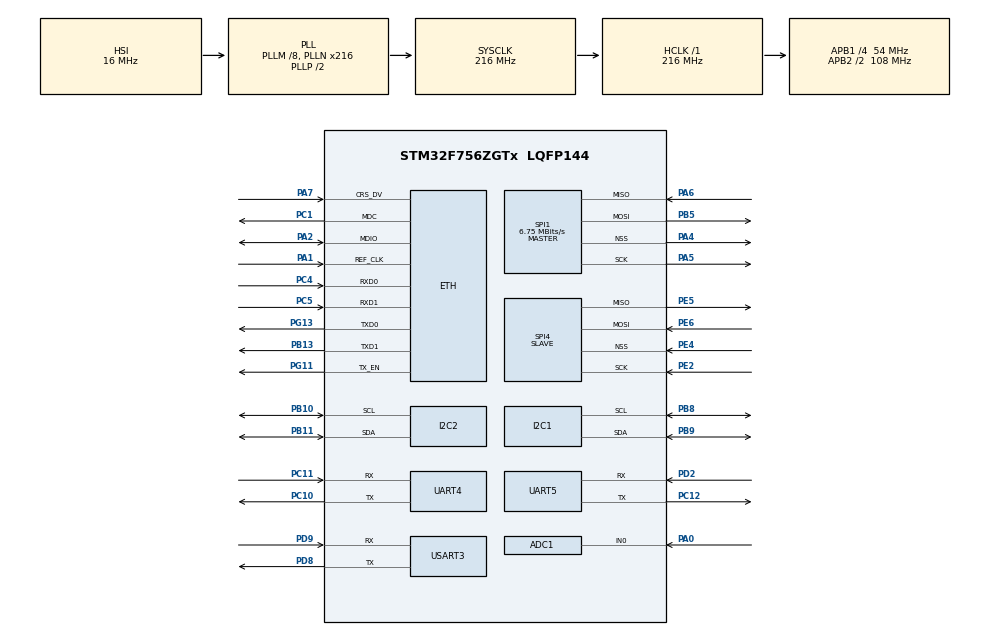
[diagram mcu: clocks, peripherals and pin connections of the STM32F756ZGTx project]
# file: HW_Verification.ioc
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ADC1.Channel-0\#ChannelRegularConversion=ADC_CHANNEL_0
ADC1.NbrOfConversionFlag=1
ADC1.Rank-0\#ChannelRegularConversion=1
ADC1.SamplingTime-0\#ChannelRegularConversion=ADC_SAMPLETIME_3CYCLES
ADC1.master=1
Dma.ADC1.10.Direction=DMA_PERIPH_TO_MEMORY
Dma.ADC1.10.FIFOMode=DMA_FIFOMODE_DISABLE
Dma.ADC1.10.Instance=DMA2_Stream4
Dma.ADC1.10.MemDataAlignment=DMA_MDATAALIGN_HALFWORD
Dma.ADC1.10.MemInc=DMA_MINC_ENABLE
Dma.ADC1.10.Mode=DMA_NORMAL
Dma.ADC1.10.PeriphDataAlignment=DMA_PDATAALIGN_HALFWORD
Dma.ADC1.10.PeriphInc=DMA_PINC_DISABLE
Dma.ADC1.10.Priority=DMA_PRIORITY_LOW
Dma.I2C1_RX.8.Direction=DMA_PERIPH_TO_MEMORY
Dma.I2C1_RX.8.FIFOMode=DMA_FIFOMODE_DISABLE
Dma.I2C1_RX.8.Instance=DMA1_Stream5
Dma.I2C1_RX.8.MemDataAlignment=DMA_MDATAALIGN_BYTE
Dma.I2C1_RX.8.MemInc=DMA_MINC_ENABLE
Dma.I2C1_RX.8.Mode=DMA_NORMAL
Dma.I2C1_RX.8.PeriphDataAlignment=DMA_PDATAALIGN_BYTE
Dma.I2C1_RX.8.PeriphInc=DMA_PINC_DISABLE
Dma.I2C1_RX.8.Priority=DMA_PRIORITY_LOW
Dma.I2C1_TX.9.Direction=DMA_MEMORY_TO_PERIPH
Dma.I2C1_TX.9.FIFOMode=DMA_FIFOMODE_DISABLE
Dma.I2C1_TX.9.Instance=DMA1_Stream6
Dma.I2C1_TX.9.MemDataAlignment=DMA_MDATAALIGN_BYTE
Dma.I2C1_TX.9.MemInc=DMA_MINC_ENABLE
Dma.I2C1_TX.9.Mode=DMA_NORMAL
Dma.I2C1_TX.9.PeriphDataAlignment=DMA_PDATAALIGN_BYTE
Dma.I2C1_TX.9.PeriphInc=DMA_PINC_DISABLE
Dma.I2C1_TX.9.Priority=DMA_PRIORITY_LOW
Dma.I2C2_RX.2.Direction=DMA_PERIPH_TO_MEMORY
Dma.I2C2_RX.2.FIFOMode=DMA_FIFOMODE_DISABLE
Dma.I2C2_RX.2.Instance=DMA1_Stream3
Dma.I2C2_RX.2.MemDataAlignment=DMA_MDATAALIGN_BYTE
Dma.I2C2_RX.2.MemInc=DMA_MINC_ENABLE
Dma.I2C2_RX.2.Mode=DMA_NORMAL
Dma.I2C2_RX.2.PeriphDataAlignment=DMA_PDATAALIGN_BYTE
Dma.I2C2_RX.2.PeriphInc=DMA_PINC_DISABLE
Dma.I2C2_RX.2.Priority=DMA_PRIORITY_LOW
Dma.I2C2_TX.3.Direction=DMA_MEMORY_TO_PERIPH
Dma.I2C2_TX.3.FIFOMode=DMA_FIFOMODE_DISABLE
Dma.I2C2_TX.3.Instance=DMA1_Stream7
Dma.I2C2_TX.3.MemDataAlignment=DMA_MDATAALIGN_BYTE
Dma.I2C2_TX.3.MemInc=DMA_MINC_ENABLE
Dma.I2C2_TX.3.Mode=DMA_NORMAL
Dma.I2C2_TX.3.PeriphDataAlignment=DMA_PDATAALIGN_BYTE
Dma.I2C2_TX.3.PeriphInc=DMA_PINC_DISABLE
Dma.I2C2_TX.3.Priority=DMA_PRIORITY_LOW
Dma.Request0=UART5_RX
Dma.Request1=UART4_RX
Dma.Request10=ADC1
Dma.Request11=TIM6_UP
Dma.Request2=I2C2_RX
Dma.Request3=I2C2_TX
Dma.Request4=SPI1_RX
Dma.Request5=SPI1_TX
Dma.Request6=SPI4_RX
Dma.Request7=SPI4_TX
Dma.Request8=I2C1_RX
Dma.Request9=I2C1_TX
Dma.SPI1_RX.4.Direction=DMA_PERIPH_TO_MEMORY
Dma.SPI1_RX.4.FIFOMode=DMA_FIFOMODE_DISABLE
Dma.SPI1_RX.4.Instance=DMA2_Stream2
Dma.SPI1_RX.4.MemDataAlignment=DMA_MDATAALIGN_BYTE
Dma.SPI1_RX.4.MemInc=DMA_MINC_ENABLE
Dma.SPI1_RX.4.Mode=DMA_NORMAL
Dma.SPI1_RX.4.PeriphDataAlignment=DMA_PDATAALIGN_BYTE
Dma.SPI1_RX.4.PeriphInc=DMA_PINC_DISABLE
Dma.SPI1_RX.4.Priority=DMA_PRIORITY_LOW
Dma.SPI1_TX.5.Direction=DMA_MEMORY_TO_PERIPH
Dma.SPI1_TX.5.FIFOMode=DMA_FIFOMODE_DISABLE
Dma.SPI1_TX.5.Instance=DMA2_Stream3
Dma.SPI1_TX.5.MemDataAlignment=DMA_MDATAALIGN_BYTE
Dma.SPI1_TX.5.MemInc=DMA_MINC_ENABLE
Dma.SPI1_TX.5.Mode=DMA_NORMAL
Dma.SPI1_TX.5.PeriphDataAlignment=DMA_PDATAALIGN_BYTE
Dma.SPI1_TX.5.PeriphInc=DMA_PINC_DISABLE
Dma.SPI1_TX.5.Priority=DMA_PRIORITY_LOW
Dma.SPI4_RX.6.Direction=DMA_PERIPH_TO_MEMORY
Dma.SPI4_RX.6.FIFOMode=DMA_FIFOMODE_DISABLE
Dma.SPI4_RX.6.Instance=DMA2_Stream0
Dma.SPI4_RX.6.MemDataAlignment=DMA_MDATAALIGN_BYTE
Dma.SPI4_RX.6.MemInc=DMA_MINC_ENABLE
Dma.SPI4_RX.6.Mode=DMA_NORMAL
Dma.SPI4_RX.6.PeriphDataAlignment=DMA_PDATAALIGN_BYTE
Dma.SPI4_RX.6.PeriphInc=DMA_PINC_DISABLE
Dma.SPI4_RX.6.Priority=DMA_PRIORITY_LOW
Dma.SPI4_TX.7.Direction=DMA_MEMORY_TO_PERIPH
Dma.SPI4_TX.7.FIFOMode=DMA_FIFOMODE_DISABLE
Dma.SPI4_TX.7.Instance=DMA2_Stream1
Dma.SPI4_TX.7.MemDataAlignment=DMA_MDATAALIGN_BYTE
Dma.SPI4_TX.7.MemInc=DMA_MINC_ENABLE
Dma.SPI4_TX.7.Mode=DMA_NORMAL
Dma.SPI4_TX.7.PeriphDataAlignment=DMA_PDATAALIGN_BYTE
Dma.SPI4_TX.7.PeriphInc=DMA_PINC_DISABLE
Dma.SPI4_TX.7.Priority=DMA_PRIORITY_LOW
Dma.TIM6_UP.11.Direction=DMA_PERIPH_TO_MEMORY
Dma.TIM6_UP.11.FIFOMode=DMA_FIFOMODE_DISABLE
Dma.TIM6_UP.11.Instance=DMA1_Stream1
Dma.TIM6_UP.11.MemDataAlignment=DMA_MDATAALIGN_WORD
Dma.TIM6_UP.11.MemInc=DMA_MINC_ENABLE
Dma.TIM6_UP.11.Mode=DMA_NORMAL
Dma.TIM6_UP.11.PeriphDataAlignment=DMA_PDATAALIGN_WORD
Dma.TIM6_UP.11.PeriphInc=DMA_PINC_DISABLE
Dma.TIM6_UP.11.Priority=DMA_PRIORITY_HIGH
Dma.UART4_RX.1.Direction=DMA_PERIPH_TO_MEMORY
Dma.UART4_RX.1.FIFOMode=DMA_FIFOMODE_DISABLE
Dma.UART4_RX.1.Instance=DMA1_Stream2
Dma.UART4_RX.1.MemDataAlignment=DMA_MDATAALIGN_BYTE
Dma.UART4_RX.1.MemInc=DMA_MINC_ENABLE
Dma.UART4_RX.1.Mode=DMA_NORMAL
Dma.UART4_RX.1.PeriphDataAlignment=DMA_PDATAALIGN_BYTE
Dma.UART4_RX.1.PeriphInc=DMA_PINC_DISABLE
Dma.UART4_RX.1.Priority=DMA_PRIORITY_LOW
Dma.UART5_RX.0.Direction=DMA_PERIPH_TO_MEMORY
Dma.UART5_RX.0.FIFOMode=DMA_FIFOMODE_DISABLE
Dma.UART5_RX.0.Instance=DMA1_Stream0
Dma.UART5_RX.0.MemDataAlignment=DMA_MDATAALIGN_BYTE
Dma.UART5_RX.0.MemInc=DMA_MINC_ENABLE
Dma.UART5_RX.0.Mode=DMA_NORMAL
Dma.UART5_RX.0.PeriphDataAlignment=DMA_PDATAALIGN_BYTE
Dma.UART5_RX.0.PeriphInc=DMA_PINC_DISABLE
Dma.UART5_RX.0.Priority=DMA_PRIORITY_LOW
ETH.MediaInterface=HAL_ETH_RMII_MODE
I2C1.Timing=0x20404768
I2C2.OwnAddress=10
I2C2.Timing=0x20404768
LWIP.BSP.number=1
LWIP.GATEWAY_ADDRESS=010.000.001.101
LWIP.IP_ADDRESS=010.000.001.100
LWIP.LWIP_DHCP=0
LWIP.NETMASK_ADDRESS=255.255.255.000
LWIP.Version=v2.1.2_Cube
LWIP0.BSP.STBoard=false
LWIP0.BSP.api=BSP_COMPONENT_DRIVER
LWIP0.BSP.component=LAN8742
LWIP0.BSP.instance=LAN8742
LWIP0.BSP.name=Driver_PHY
LWIP0.BSP.semaphore=S_LAN8742
LWIP0.BSP.solution=LAN8742
Mcu.Family=STM32F7
Mcu.Name=STM32F756ZGTx
Mcu.Package=LQFP144
NVIC.DMA1_Stream0_IRQn=true\:0\:0\:false\:false\:true\:false\:true\:true
NVIC.DMA1_Stream1_IRQn=true\:0\:0\:false\:false\:true\:false\:true\:true
NVIC.DMA1_Stream2_IRQn=true\:0\:0\:false\:false\:true\:false\:true\:true
NVIC.DMA1_Stream3_IRQn=true\:0\:0\:false\:false\:true\:false\:true\:true
NVIC.DMA1_Stream5_IRQn=true\:0\:0\:false\:false\:true\:false\:true\:true
NVIC.DMA1_Stream6_IRQn=true\:0\:0\:false\:false\:true\:false\:true\:true
NVIC.DMA1_Stream7_IRQn=true\:0\:0\:false\:false\:true\:false\:true\:true
NVIC.DMA2_Stream0_IRQn=true\:0\:0\:false\:false\:true\:false\:true\:true
NVIC.DMA2_Stream1_IRQn=true\:0\:0\:false\:false\:true\:false\:true\:true
NVIC.DMA2_Stream2_IRQn=true\:0\:0\:false\:false\:true\:false\:true\:true
NVIC.DMA2_Stream3_IRQn=true\:0\:0\:false\:false\:true\:false\:true\:true
NVIC.DMA2_Stream4_IRQn=true\:0\:0\:false\:false\:true\:false\:true\:true
NVIC.ETH_IRQn=true\:0\:0\:false\:false\:true\:true\:true\:true
NVIC.ETH_WKUP_IRQn=true\:0\:0\:false\:false\:true\:true\:true\:true
NVIC.I2C1_ER_IRQn=true\:0\:0\:false\:false\:true\:true\:true\:true
NVIC.I2C1_EV_IRQn=true\:0\:0\:false\:false\:true\:true\:true\:true
NVIC.I2C2_ER_IRQn=true\:0\:0\:false\:false\:true\:true\:true\:true
NVIC.I2C2_EV_IRQn=true\:0\:0\:false\:false\:true\:true\:true\:true
NVIC.PriorityGroup=NVIC_PRIORITYGROUP_4
NVIC.SPI1_IRQn=true\:0\:0\:false\:false\:true\:true\:true\:true
NVIC.SPI4_IRQn=true\:0\:0\:false\:false\:true\:true\:true\:true
NVIC.TIM6_DAC_IRQn=true\:0\:0\:false\:false\:true\:true\:true\:true
NVIC.UART4_IRQn=true\:0\:0\:false\:false\:true\:true\:true\:true
NVIC.UART5_IRQn=true\:0\:0\:false\:false\:true\:true\:true\:true
NVIC.USART3_IRQn=true\:0\:0\:false\:false\:true\:true\:true\:true
PA0/WKUP.Signal=ADCx_IN0
PA1.Mode=RMII
PA1.Signal=ETH_REF_CLK
PA13.Mode=Serial_Wire
PA13.Signal=SYS_JTMS-SWDIO
PA14.Mode=Serial_Wire
PA14.Signal=SYS_JTCK-SWCLK
PA2.Mode=RMII
PA2.Signal=ETH_MDIO
PA4.Mode=NSS_Signal_Hard_Output
PA4.Signal=SPI1_NSS
PA5.Mode=Full_Duplex_Master
PA5.Signal=SPI1_SCK
PA6.Mode=Full_Duplex_Master
PA6.Signal=SPI1_MISO
PA7.Mode=RMII
PA7.Signal=ETH_CRS_DV
PB10.GPIO_Pu=GPIO_PULLUP
PB10.Mode=I2C
PB10.Signal=I2C2_SCL
PB11.GPIO_Pu=GPIO_PULLUP
PB11.Mode=I2C
PB11.Signal=I2C2_SDA
PB13.Mode=RMII
PB13.Signal=ETH_TXD1
PB5.Mode=Full_Duplex_Master
PB5.Signal=SPI1_MOSI
PB8.GPIO_Pu=GPIO_PULLUP
PB8.Mode=I2C
PB8.Signal=I2C1_SCL
PB9.GPIO_Pu=GPIO_PULLUP
PB9.Mode=I2C
PB9.Signal=I2C1_SDA
PC1.Mode=RMII
PC1.Signal=ETH_MDC
PC10.Mode=Asynchronous
PC10.Signal=UART4_TX
PC11.Mode=Asynchronous
PC11.Signal=UART4_RX
PC12.Mode=Asynchronous
PC12.Signal=UART5_TX
PC4.Mode=RMII
PC4.Signal=ETH_RXD0
PC5.Mode=RMII
PC5.Signal=ETH_RXD1
PD2.Mode=Asynchronous
PD2.Signal=UART5_RX
PD8.Mode=Asynchronous
PD8.Signal=USART3_TX
PD9.Mode=Asynchronous
PD9.Signal=USART3_RX
PE2.Mode=Full_Duplex_Slave
PE2.Signal=SPI4_SCK
PE4.Mode=NSS_Signal_Hard_Input
PE4.Signal=SPI4_NSS
PE5.Mode=Full_Duplex_Slave
PE5.Signal=SPI4_MISO
PE6.Mode=Full_Duplex_Slave
PE6.Signal=SPI4_MOSI
PG11.Mode=RMII
PG11.Signal=ETH_TX_EN
PG13.Mode=RMII
PG13.Signal=ETH_TXD0
ProjectManager.HeapSize=0x200
ProjectManager.StackSize=0x400
ProjectManager.TargetToolchain=STM32CubeIDE
RCC.AHBFreq_Value=216000000
RCC.APB1CLKDivider=RCC_HCLK_DIV4
RCC.APB1Freq_Value=54000000
RCC.APB1TimFreq_Value=108000000
RCC.APB2CLKDivider=RCC_HCLK_DIV2
RCC.APB2Freq_Value=108000000
RCC.APB2TimFreq_Value=216000000
RCC.CortexFreq_Value=216000000
RCC.HCLKFreq_Value=216000000
RCC.HSE_VALUE=25000000
RCC.HSI_VALUE=16000000
RCC.LSE_VALUE=32768
RCC.PLLM=8
RCC.PLLN=216
RCC.SYSCLKFreq_VALUE=216000000
RCC.SYSCLKSource=RCC_SYSCLKSOURCE_PLLCLK
RCC.USBFreq_Value=216000000
RCC.VCOOutputFreq_Value=432000000
SH.ADCx_IN0.0=ADC1_IN0,IN0
SPI1.BaudRatePrescaler=SPI_BAUDRATEPRESCALER_16
SPI1.CalculateBaudRate=6.75 MBits/s
SPI1.DataSize=SPI_DATASIZE_8BIT
SPI1.Direction=SPI_DIRECTION_2LINES
SPI1.Mode=SPI_MODE_MASTER
SPI1.VirtualNSS=VM_NSSHARD
SPI1.VirtualType=VM_MASTER
SPI4.DataSize=SPI_DATASIZE_8BIT
SPI4.Direction=SPI_DIRECTION_2LINES
SPI4.Mode=SPI_MODE_SLAVE
SPI4.VirtualNSS=VM_NSSHARD
SPI4.VirtualType=VM_SLAVE
TIM6.Period=1000-1
TIM6.Prescaler=5400-1
TIM6.TIM_MasterOutputTrigger=TIM_TRGO_UPDATE
USART3.VirtualMode-Asynchronous=VM_ASYNC
VP_CRC_VS_CRC.Mode=CRC_Activate
VP_LWIP_VS_Enabled.Mode=Enabled
VP_TIM2_VS_ClockSourceINT.Mode=Internal
VP_TIM6_VS_ClockSourceINT.Mode=Enable_Timer
board=custom

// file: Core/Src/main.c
/* USER CODE BEGIN Header */
/**
  ******************************************************************************
  * @file           : main.c
  * @brief          : Main program body
  ******************************************************************************
  * @attention
  *
  * Copyright (c) 2025 STMicroelectronics.
  * All rights reserved.
  *
  * This software is licensed under terms that can be found in the LICENSE file
  * in the root directory of this software component.
  * If no LICENSE file comes with this software, it is provided AS-IS.
  *
  ******************************************************************************
  */
/* USER CODE END Header */
#include "main.h"
#include "adc.h"
#include "crc.h"
#include "dma.h"
#include "i2c.h"
#include "lwip.h"
#include "spi.h"
#include "tim.h"
#include "usart.h"
#include "gpio.h"

/* USER CODE BEGIN Includes */
#include "hw_verif.h"
/* USER CODE END Includes */

/* USER CODE BEGIN PD */
#define UART_DEBUG &huart3
/* USER CODE END PD */

void SystemClock_Config(void);

/* USER CODE BEGIN 0 */
int __io_putchar(int ch) {
	HAL_UART_Transmit(UART_DEBUG, (uint8_t*) &ch, 1, 0xFFFF);
	return ch;
}

int _write(int file, char *ptr, int len) {
	char *cr = "\r";
	HAL_UART_Transmit(UART_DEBUG, (uint8_t*) ptr, len, 0xFFFF);
	HAL_UART_Transmit(UART_DEBUG, (uint8_t*) cr, 1, 0xFFFF);
	return len + 1;
}
/* USER CODE END 0 */

int main(void)
{

  /* MCU Configuration--------------------------------------------------------*/

  /* Reset of all peripherals, Initializes the Flash interface and the Systick. */
  HAL_Init();

  /* Configure the system clock */
  SystemClock_Config();

  /* Initialize all configured peripherals */
  MX_GPIO_Init();
  MX_DMA_Init();
  MX_USART3_UART_Init();
  MX_LWIP_Init();
  MX_CRC_Init();
  MX_UART4_Init();
  MX_UART5_Init();
  MX_I2C1_Init();
  MX_I2C2_Init();
  MX_SPI1_Init();
  MX_SPI4_Init();
  MX_ADC1_Init();
  MX_TIM6_Init();
  MX_TIM2_Init();
  /* USER CODE BEGIN 2 */
  HW_Verification_Proccess();
  /* USER CODE END 2 */

  /* Infinite loop */
  while (1)
  {

  }
}

void SystemClock_Config(void)
{
  RCC_OscInitTypeDef RCC_OscInitStruct = {0};
  RCC_ClkInitTypeDef RCC_ClkInitStruct = {0};

  /** Configure the main internal regulator output voltage
  */
  __HAL_RCC_PWR_CLK_ENABLE();
  __HAL_PWR_VOLTAGESCALING_CONFIG(PWR_REGULATOR_VOLTAGE_SCALE1);

  /** Initializes the RCC Oscillators according to the specified parameters
  * in the RCC_OscInitTypeDef structure.
  */
  RCC_OscInitStruct.OscillatorType = RCC_OSCILLATORTYPE_HSI;
  RCC_OscInitStruct.HSIState = RCC_HSI_ON;
  RCC_OscInitStruct.HSICalibrationValue = RCC_HSICALIBRATION_DEFAULT;
  RCC_OscInitStruct.PLL.PLLState = RCC_PLL_ON;
  RCC_OscInitStruct.PLL.PLLSource = RCC_PLLSOURCE_HSI;
  RCC_OscInitStruct.PLL.PLLM = 8;
  RCC_OscInitStruct.PLL.PLLN = 216;
  RCC_OscInitStruct.PLL.PLLP = RCC_PLLP_DIV2;
  RCC_OscInitStruct.PLL.PLLQ = 2;
  if (HAL_RCC_OscConfig(&RCC_OscInitStruct) != HAL_OK)
  {
    Error_Handler();
  }

  /** Activate the Over-Drive mode
  */
  if (HAL_PWREx_EnableOverDrive() != HAL_OK)
  {
    Error_Handler();
  }

  /** Initializes the CPU, AHB and APB buses clocks
  */
  RCC_ClkInitStruct.ClockType = RCC_CLOCKTYPE_HCLK|RCC_CLOCKTYPE_SYSCLK
                              |RCC_CLOCKTYPE_PCLK1|RCC_CLOCKTYPE_PCLK2;
  RCC_ClkInitStruct.SYSCLKSource = RCC_SYSCLKSOURCE_PLLCLK;
  RCC_ClkInitStruct.AHBCLKDivider = RCC_SYSCLK_DIV1;
  RCC_ClkInitStruct.APB1CLKDivider = RCC_HCLK_DIV4;
  RCC_ClkInitStruct.APB2CLKDivider = RCC_HCLK_DIV2;

  if (HAL_RCC_ClockConfig(&RCC_ClkInitStruct, FLASH_LATENCY_7) != HAL_OK)
  {
    Error_Handler();
  }
}

void Error_Handler(void)
{
  __disable_irq();
  while (1)
  {
  }
}
